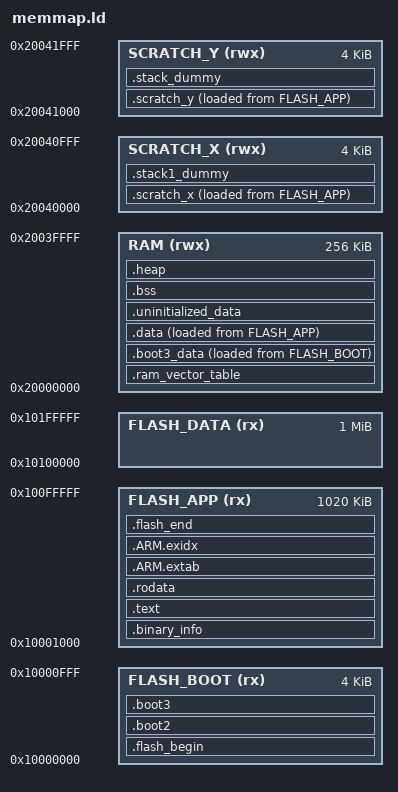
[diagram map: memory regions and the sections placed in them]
/* Based on GCC ARM embedded samples.
   Defines the following symbols for use by code:
    __exidx_start
    __exidx_end
    __etext
    __data_start__
    __preinit_array_start
    __preinit_array_end
    __init_array_start
    __init_array_end
    __fini_array_start
    __fini_array_end
    __data_end__
    __bss_start__
    __bss_end__
    __end__
    end
    __HeapLimit
    __StackLimit
    __StackTop
    __stack (== StackTop)
*/

MEMORY
{
    FLASH_BOOT(rx) : ORIGIN = 0x10000000, LENGTH = 4k
    FLASH_APP(rx) : ORIGIN = 0x10000000 + 4k, LENGTH = 1020k
    FLASH_DATA(rx) : ORIGIN = 0x10000000 + 1024k, LENGTH = 1024k
    RAM(rwx) : ORIGIN =  0x20000000, LENGTH = 256k
    SCRATCH_X(rwx) : ORIGIN = 0x20040000, LENGTH = 4k
    SCRATCH_Y(rwx) : ORIGIN = 0x20041000, LENGTH = 4k
}

ENTRY(_entry_point)

SECTIONS
{
    /* Second stage bootloader is prepended to the image. It must be 256 bytes big
       and checksummed. It is usually built by the boot_stage2 target
       in the Raspberry Pi Pico SDK
    */

    .flash_begin : {
        __flash_binary_start = .;
    } > FLASH_BOOT

    .boot2 : {
        __boot2_start__ = .;
        KEEP (*(.boot2))
        __boot2_end__ = .;
    } > FLASH_BOOT

    ASSERT(__boot2_end__ - __boot2_start__ == 256,
        "ERROR: Pico second stage bootloader must be 256 bytes in size")

    /* The second stage will always enter the image at the start of .text.
       The debugger will use the ELF entry point, which is the _entry_point
       symbol if present, otherwise defaults to start of .text.
       This can be used to transfer control back to the bootrom on debugger
       launches only, to perform proper flash setup.
    */

    .boot3 : {
        __boot3_start = .;
        KEEP(core/module/pico-core/src/boot_stage3/CMakeFiles/boot3.dir/boot3.c.obj(.rodata))

        LONG(0x7188ebf2)
        LONG(__binary_info_start)
        LONG(__binary_info_end)
        LONG(data_cpy_table)
        LONG(0xe71aa390)
        __binary_info_header_end = .;

        KEEP(core/module/pico-core/src/boot_stage3/CMakeFiles/boot3.dir/boot3.c.obj(.text))
    } > FLASH_BOOT

   .ram_vector_table (NOLOAD): {
        *(.ram_vector_table)
    } > RAM

    .boot3_data : {
        __boot3_data_start__ = .;
        KEEP(core/module/pico-core/src/boot_stage3/CMakeFiles/boot3.dir/boot3.c.obj(.time_critical*))
        __boot3_data_end__ = .;
    } > RAM AT> FLASH_BOOT
    __boot3_data_source__ = LOADADDR(.boot3_data);

    /* Machine inspectable binary information */
    . = ALIGN(4);
    .binary_info :
    {
        __logical_binary_start = .;
        KEEP (*(.vectors))

        __binary_info_start = .;
        KEEP(*(.binary_info.keep.*))
        *(.binary_info.*)

        data_cpy_table = .;
        LONG(__etext)
        LONG(__data_start__)
        LONG(__data_end__)
        LONG(__scratch_x_source__)
        LONG(__scratch_x_start__)
        LONG(__scratch_x_end__)
        LONG(__scratch_y_source__)
        LONG(__scratch_y_start__)
        LONG(__scratch_y_end__)
        LONG(0) /* null terminator */
        __binary_info_end = .;
    } > FLASH_APP
    . = ALIGN(4);

    .text : {
        KEEP (*(.reset))
        /* TODO revisit this now memset/memcpy/float in ROM */
        /* bit of a hack right now to exclude all floating point and time critical (e.g. memset, memcpy) code from
         * FLASH ... we will include any thing excluded here in .data below by default */
        *(.init)
        *(EXCLUDE_FILE(*libgcc.a: *libc.a:*lib_a-mem*.o *libm.a:) .text*)
        *(.fini)
        /* Pull all c'tors into .text */
        *crtbegin.o(.ctors)
        *crtbegin?.o(.ctors)
        *(EXCLUDE_FILE(*crtend?.o *crtend.o) .ctors)
        *(SORT(.ctors.*))
        *(.ctors)
        /* Followed by destructors */
        *crtbegin.o(.dtors)
        *crtbegin?.o(.dtors)
        *(EXCLUDE_FILE(*crtend?.o *crtend.o) .dtors)
        *(SORT(.dtors.*))
        *(.dtors)

        *(.eh_frame*)
        . = ALIGN(4);
    } > FLASH_APP

    .rodata : {
        *(EXCLUDE_FILE(*libgcc.a: *libc.a:*lib_a-mem*.o *libm.a:) .rodata*)
        . = ALIGN(4);
        *(SORT_BY_ALIGNMENT(SORT_BY_NAME(.flashdata*)))
        . = ALIGN(4);
    } > FLASH_APP

    .ARM.extab :
    {
        *(.ARM.extab* .gnu.linkonce.armextab.*)
    } > FLASH_APP

    .ARM.exidx :
    {
        __exidx_start = .;
        *(.ARM.exidx* .gnu.linkonce.armexidx.*)
        __exidx_end = .;
    } > FLASH_APP

    .data : {
        __data_start__ = .;
        *(vtable)

        *(.time_critical*)

        /* remaining .text and .rodata; i.e. stuff we exclude above because we want it in RAM */
        *(.text*)
        . = ALIGN(4);
        *(.rodata*)
        . = ALIGN(4);

        *(.data*)

        . = ALIGN(4);
        *(.after_data.*)
        . = ALIGN(4);
        /* preinit data */
        PROVIDE_HIDDEN (__mutex_array_start = .);
        KEEP(*(SORT(.mutex_array.*)))
        KEEP(*(.mutex_array))
        PROVIDE_HIDDEN (__mutex_array_end = .);

        . = ALIGN(4);
        /* preinit data */
        PROVIDE_HIDDEN (__preinit_array_start = .);
        KEEP(*(SORT(.preinit_array.*)))
        KEEP(*(.preinit_array))
        PROVIDE_HIDDEN (__preinit_array_end = .);

        . = ALIGN(4);
        /* init data */
        PROVIDE_HIDDEN (__init_array_start = .);
        KEEP(*(SORT(.init_array.*)))
        KEEP(*(.init_array))
        PROVIDE_HIDDEN (__init_array_end = .);

        . = ALIGN(4);
        /* finit data */
        PROVIDE_HIDDEN (__fini_array_start = .);
        *(SORT(.fini_array.*))
        *(.fini_array)
        PROVIDE_HIDDEN (__fini_array_end = .);

        *(.jcr)
        . = ALIGN(4);
        /* All data end */
        __data_end__ = .;
    } > RAM AT> FLASH_APP
    /* __etext is (for backwards compatibility) the name of the .data init source pointer (...) */
    __etext = LOADADDR(.data);

    .uninitialized_data (NOLOAD): {
        . = ALIGN(4);
        *(.uninitialized_data*)
    } > RAM

    /* Start and end symbols must be word-aligned */
    .scratch_x : {
        __scratch_x_start__ = .;
        *(.scratch_x.*)
        . = ALIGN(4);
        __scratch_x_end__ = .;
    } > SCRATCH_X AT > FLASH_APP
    __scratch_x_source__ = LOADADDR(.scratch_x);

    .scratch_y : {
        __scratch_y_start__ = .;
        *(.scratch_y.*)
        . = ALIGN(4);
        __scratch_y_end__ = .;
    } > SCRATCH_Y AT > FLASH_APP
    __scratch_y_source__ = LOADADDR(.scratch_y);

    .bss  : {
        . = ALIGN(4);
        __bss_start__ = .;
        *(SORT_BY_ALIGNMENT(SORT_BY_NAME(.bss*)))
        *(COMMON)
        . = ALIGN(4);
        __bss_end__ = .;
    } > RAM

    .heap (NOLOAD):
    {
        __end__ = .;
        end = __end__;
        KEEP(*(.heap*))
        __HeapLimit = .;
    } > RAM

    /* .stack*_dummy section doesn't contains any symbols. It is only
     * used for linker to calculate size of stack sections, and assign
     * values to stack symbols later
     *
     * stack1 section may be empty/missing if platform_launch_core1 is not used */

    /* by default we put core 0 stack at the end of scratch Y, so that if core 1
     * stack is not used then all of SCRATCH_X is free.
     */
    .stack1_dummy (NOLOAD):
    {
        *(.stack1*)
    } > SCRATCH_X
    .stack_dummy (NOLOAD):
    {
        KEEP(*(.stack*))
    } > SCRATCH_Y

    .flash_end : {
        PROVIDE(__flash_binary_end = .);
    } > FLASH_APP

    /* stack limit is poorly named, but historically is maximum heap ptr */
    __StackLimit = ORIGIN(RAM) + LENGTH(RAM);
    __StackOneTop = ORIGIN(SCRATCH_X) + LENGTH(SCRATCH_X);
    __StackTop = ORIGIN(SCRATCH_Y) + LENGTH(SCRATCH_Y);
    __StackOneBottom = __StackOneTop - SIZEOF(.stack1_dummy);
    __StackBottom = __StackTop - SIZEOF(.stack_dummy);
    PROVIDE(__stack = __StackTop);

    __flash_app_start__ = ORIGIN(FLASH_APP);
    __flash_app_end__ = ORIGIN(FLASH_APP) + LENGTH(FLASH_APP);
    __flash_data_start__ = ORIGIN(FLASH_DATA);
    __flash_data_end__ = ORIGIN(FLASH_DATA) + LENGTH(FLASH_DATA);

    /* Check if data + heap + stack exceeds RAM limit */
    ASSERT(__StackLimit >= __HeapLimit, "region RAM overflowed")

    ASSERT( __binary_info_header_end - __boot3_start <= 256, "Binary info must be in first 256 bytes of the binary")
    /* todo assert on extra code */
}
